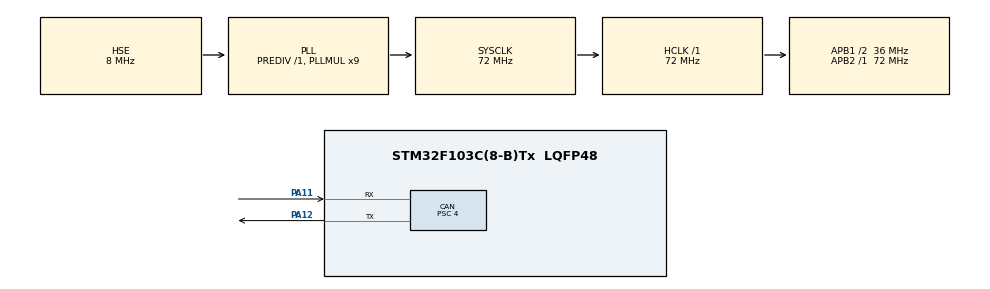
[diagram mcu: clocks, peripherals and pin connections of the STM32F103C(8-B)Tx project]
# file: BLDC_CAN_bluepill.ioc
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CAN.BS1=CAN_BS1_14TQ
CAN.BS2=CAN_BS2_3TQ
CAN.CalculateBaudRate=500000
CAN.CalculateTimeBit=2000
CAN.CalculateTimeQuantum=111.11111111111111
CAN.NART=ENABLE
CAN.Prescaler=4
Mcu.Family=STM32F1
Mcu.Name=STM32F103C(8-B)Tx
Mcu.Package=LQFP48
NVIC.CAN1_RX1_IRQn=true\:0\:0\:false\:false\:true\:true\:true\:true
NVIC.PriorityGroup=NVIC_PRIORITYGROUP_4
PA11.Mode=CAN_Activate
PA11.Signal=CAN_RX
PA12.Mode=CAN_Activate
PA12.Signal=CAN_TX
PC14-OSC32_IN.Mode=LSE-External-Oscillator
PC14-OSC32_IN.Signal=RCC_OSC32_IN
PC15-OSC32_OUT.Mode=LSE-External-Oscillator
PC15-OSC32_OUT.Signal=RCC_OSC32_OUT
PD0-OSC_IN.Mode=HSE-External-Oscillator
PD0-OSC_IN.Signal=RCC_OSC_IN
PD1-OSC_OUT.Mode=HSE-External-Oscillator
PD1-OSC_OUT.Signal=RCC_OSC_OUT
ProjectManager.HeapSize=0x200
ProjectManager.StackSize=0x400
ProjectManager.TargetToolchain=STM32CubeIDE
RCC.AHBFreq_Value=72000000
RCC.APB1CLKDivider=RCC_HCLK_DIV2
RCC.APB1Freq_Value=36000000
RCC.APB1TimFreq_Value=72000000
RCC.APB2Freq_Value=72000000
RCC.APB2TimFreq_Value=72000000
RCC.HCLKFreq_Value=72000000
RCC.PLLMUL=RCC_PLL_MUL9
RCC.PLLSourceVirtual=RCC_PLLSOURCE_HSE
RCC.SYSCLKFreq_VALUE=72000000
RCC.SYSCLKSource=RCC_SYSCLKSOURCE_PLLCLK
RCC.USBFreq_Value=72000000
VP_SYS_VS_ND.Mode=No_Debug
board=custom

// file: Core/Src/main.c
/* USER CODE BEGIN Header */
/**
  ******************************************************************************
  * @file           : main.c
  * @brief          : Main program body
  ******************************************************************************
  * @attention
  *
  * Copyright (c) 2025 STMicroelectronics.
  * All rights reserved.
  *
  * This software is licensed under terms that can be found in the LICENSE file
  * in the root directory of this software component.
  * If no LICENSE file comes with this software, it is provided AS-IS.
  *
  ******************************************************************************
  */
/* USER CODE END Header */
#include "main.h"

CAN_HandleTypeDef hcan;

void SystemClock_Config(void);
static void MX_GPIO_Init(void);
static void MX_CAN_Init(void);

int main(void)
{

  /* MCU Configuration--------------------------------------------------------*/

  /* Reset of all peripherals, Initializes the Flash interface and the Systick. */
  HAL_Init();

  /* Configure the system clock */
  SystemClock_Config();

  /* Initialize all configured peripherals */
  MX_GPIO_Init();
  MX_CAN_Init();
  /* USER CODE BEGIN 2 */
  HAL_CAN_Start(&hcan);

  CAN_TxHeaderTypeDef txHeader;
  uint8_t ControllerID = 0x01;
  txHeader.StdId = 0x41 << 4 | ControllerID; //To clear all fault codes.
  txHeader.IDE = CAN_ID_STD;
  txHeader.RTR = CAN_RTR_DATA;
  txHeader.DLC = 8;

  uint8_t txData_8[8] = {0};

  uint32_t mailbox;

  /* USER CODE END 2 */

  /* Infinite loop */
  /* USER CODE BEGIN WHILE */
  while (1)
  {
	  HAL_CAN_AddTxMessage(&hcan, &txHeader, txData_8, &mailbox); //clear faults
	  HAL_Delay(1000);
	  txHeader.StdId = 0x20 << 4 | ControllerID;
	  HAL_CAN_AddTxMessage(&hcan, &txHeader, txData_8, &mailbox); //calibrate motor
	  HAL_Delay(40000); //40 seconds
	  //open loop turning:
	  txHeader.StdId = 0x53 << 4 | ControllerID; //open loop mode
	  txHeader.DLC = 2;
	  uint8_t txData_2[2];
	  txData_2[0] = 0x10;
	  txData_2[1] = 0x27;
	  HAL_CAN_AddTxMessage(hcan, &txHeader, txData_2, &mailbox); //open loop 10,000 power run
	  HAL_Delay(10000); //runs for 10 seconds

    /* USER CODE END WHILE */

  }
}

void SystemClock_Config(void)
{
  RCC_OscInitTypeDef RCC_OscInitStruct = {0};
  RCC_ClkInitTypeDef RCC_ClkInitStruct = {0};

  /** Initializes the RCC Oscillators according to the specified parameters
  * in the RCC_OscInitTypeDef structure.
  */
  RCC_OscInitStruct.OscillatorType = RCC_OSCILLATORTYPE_HSE;
  RCC_OscInitStruct.HSEState = RCC_HSE_ON;
  RCC_OscInitStruct.HSEPredivValue = RCC_HSE_PREDIV_DIV1;
  RCC_OscInitStruct.HSIState = RCC_HSI_ON;
  RCC_OscInitStruct.PLL.PLLState = RCC_PLL_ON;
  RCC_OscInitStruct.PLL.PLLSource = RCC_PLLSOURCE_HSE;
  RCC_OscInitStruct.PLL.PLLMUL = RCC_PLL_MUL9;
  if (HAL_RCC_OscConfig(&RCC_OscInitStruct) != HAL_OK)
  {
    Error_Handler();
  }

  /** Initializes the CPU, AHB and APB buses clocks
  */
  RCC_ClkInitStruct.ClockType = RCC_CLOCKTYPE_HCLK|RCC_CLOCKTYPE_SYSCLK
                              |RCC_CLOCKTYPE_PCLK1|RCC_CLOCKTYPE_PCLK2;
  RCC_ClkInitStruct.SYSCLKSource = RCC_SYSCLKSOURCE_PLLCLK;
  RCC_ClkInitStruct.AHBCLKDivider = RCC_SYSCLK_DIV1;
  RCC_ClkInitStruct.APB1CLKDivider = RCC_HCLK_DIV2;
  RCC_ClkInitStruct.APB2CLKDivider = RCC_HCLK_DIV1;

  if (HAL_RCC_ClockConfig(&RCC_ClkInitStruct, FLASH_LATENCY_2) != HAL_OK)
  {
    Error_Handler();
  }
}

static void MX_CAN_Init(void)
{

  hcan.Instance = CAN1;
  hcan.Init.Prescaler = 4;
  hcan.Init.Mode = CAN_MODE_NORMAL;
  hcan.Init.SyncJumpWidth = CAN_SJW_1TQ;
  hcan.Init.TimeSeg1 = CAN_BS1_14TQ;
  hcan.Init.TimeSeg2 = CAN_BS2_3TQ;
  hcan.Init.TimeTriggeredMode = DISABLE;
  hcan.Init.AutoBusOff = DISABLE;
  hcan.Init.AutoWakeUp = DISABLE;
  hcan.Init.AutoRetransmission = ENABLE;
  hcan.Init.ReceiveFifoLocked = DISABLE;
  hcan.Init.TransmitFifoPriority = DISABLE;
  if (HAL_CAN_Init(&hcan) != HAL_OK)
  {
    Error_Handler();
  }

}

static void MX_GPIO_Init(void)
{

  /* GPIO Ports Clock Enable */
  __HAL_RCC_GPIOC_CLK_ENABLE();
  __HAL_RCC_GPIOD_CLK_ENABLE();
  __HAL_RCC_GPIOA_CLK_ENABLE();

}

void Error_Handler(void)
{
  __disable_irq();
  while (1)
  {
  }
}
